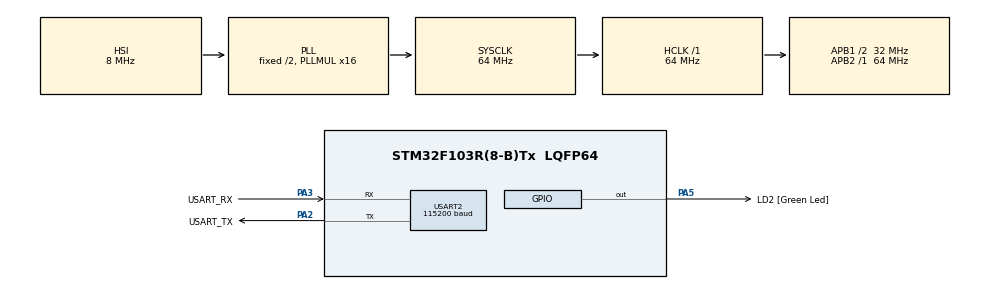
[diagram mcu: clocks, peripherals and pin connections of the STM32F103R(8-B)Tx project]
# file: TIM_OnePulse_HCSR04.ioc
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Mcu.Family=STM32F1
Mcu.Name=STM32F103R(8-B)Tx
Mcu.Package=LQFP64
NVIC.PriorityGroup=NVIC_PRIORITYGROUP_4
NVIC.TIM2_IRQn=true\:1\:0\:false\:false\:true\:true\:true\:true
PA0-WKUP.GPIO_PuPd=GPIO_PULLDOWN
PA0-WKUP.Signal=S_TIM2_CH1
PA13.GPIO_Label=TMS
PA13.Mode=Serial_Wire
PA13.Signal=SYS_JTMS-SWDIO
PA14.GPIO_Label=TCK
PA14.Mode=Serial_Wire
PA14.Signal=SYS_JTCK-SWCLK
PA2.GPIO_Label=USART_TX
PA2.GPIO_Mode=GPIO_MODE_AF_PP
PA2.GPIO_PuPd=GPIO_NOPULL
PA2.GPIO_Speed=GPIO_SPEED_FREQ_LOW
PA2.Mode=Asynchronous
PA2.Signal=USART2_TX
PA3.GPIO_Label=USART_RX
PA3.GPIO_PuPd=GPIO_NOPULL
PA3.GPIO_Speed=GPIO_SPEED_FREQ_LOW
PA3.Mode=Asynchronous
PA3.Signal=USART2_RX
PA5.GPIO_Label=LD2 [Green Led]
PA5.GPIO_ModeDefaultOutputPP=GPIO_MODE_OUTPUT_PP
PA5.GPIO_PuPd=GPIO_NOPULL
PA5.GPIO_Speed=GPIO_SPEED_FREQ_LOW
PA5.Signal=GPIO_Output
PA6.GPIO_Speed=GPIO_SPEED_FREQ_HIGH
PA6.Signal=S_TIM3_CH1
PB3.GPIO_Label=SWO
PB3.Signal=SYS_JTDO-TRACESWO
PC14-OSC32_IN.Mode=LSE-External-Oscillator
PC14-OSC32_IN.Signal=RCC_OSC32_IN
PC15-OSC32_OUT.Mode=LSE-External-Oscillator
PC15-OSC32_OUT.Signal=RCC_OSC32_OUT
PD0-OSC_IN.Mode=HSE-External-Clock-Source
PD0-OSC_IN.Signal=RCC_OSC_IN
PD1-OSC_OUT.Mode=HSE-External-Clock-Source
PD1-OSC_OUT.Signal=RCC_OSC_OUT
ProjectManager.HeapSize=0x200
ProjectManager.StackSize=0x400
ProjectManager.TargetToolchain=STM32CubeIDE
RCC.AHBFreq_Value=64000000
RCC.APB1CLKDivider=RCC_HCLK_DIV2
RCC.APB1Freq_Value=32000000
RCC.APB1TimFreq_Value=64000000
RCC.APB2Freq_Value=64000000
RCC.APB2TimFreq_Value=64000000
RCC.HCLKFreq_Value=64000000
RCC.PLLMUL=RCC_PLL_MUL16
RCC.RTCClockSelection=RCC_RTCCLKSOURCE_LSE
RCC.SYSCLKFreq_VALUE=64000000
RCC.SYSCLKSource=RCC_SYSCLKSOURCE_PLLCLK
RCC.USBFreq_Value=64000000
TIM2.Channel-Input_Capture1_from_TI1=TIM_CHANNEL_1
TIM2.Channel-Input_Capture2_from_TI1=TIM_CHANNEL_2
TIM2.IC2Polarity=TIM_INPUTCHANNELPOLARITY_FALLING
TIM2.IC2Selection=TIM_ICSELECTION_INDIRECTTI
TIM2.Period=65535
TIM2.Prescaler=63
TIM3.Channel-PWM Generation1 CH1=TIM_CHANNEL_1
TIM3.OCMode_1=TIM_OCMODE_PWM2
TIM3.Period=11
TIM3.Prescaler=63
TIM3.Pulse-PWM Generation1 CH1=2
USART2.BaudRate=115200
USART2.VirtualMode=VM_ASYNC
VP_TIM2_VS_ClockSourceINT.Mode=Internal
VP_TIM3_VS_ClockSourceINT.Mode=Internal
board=NUCLEO-F103RB

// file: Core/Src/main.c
/* USER CODE BEGIN Header */
/**
 ******************************************************************************
 * @file           : main.c
 * @brief          : Main program body
 ******************************************************************************
 * @attention
 *
 * Copyright (c) 2026 STMicroelectronics.
 * All rights reserved.
 *
 * This software is licensed under terms that can be found in the LICENSE file
 * in the root directory of this software component.
 * If no LICENSE file comes with this software, it is provided AS-IS.
 *
 ******************************************************************************
 */
/**
 * 10_TIM_OnePulse_HCSR04_c  —  [계층: HAL + 레지스터(OPM 비트)]  원 펄스 모드로 10us 트리거 + 입력 캡처로 초음파 거리 측정
 *
 * HC-SR04 초음파 센서 프로토콜
 *   TRIG 핀에 10us 이상의 High 펄스 -> 센서가 40kHz 초음파 8발 송출 -> ECHO 핀이 "왕복 시간" 동안 High
 *   거리[cm] = ECHO 폭[us] / 58   (음속 343m/s, 왕복이므로 /2)
 *
 * 배선 (Nucleo-F103RB)
 *   VCC = 5V, GND = GND
 *   TRIG = PA6 ('D12', TIM3_CH1)   <- 타이머 원 펄스 출력
 *   ECHO = PA0 ('A0', TIM2_CH1/CH2 입력 캡처)  *** ECHO 는 5V 신호이므로 저항 분압(예: 1kΩ + 2kΩ)으로 3.3V 이하로 낮출 것 ***
 *
 * 원 펄스 모드(OPM) (RM0008 15.3.10)
 *   TIM3->CR1.OPM = 1 : 카운터가 다음 업데이트 이벤트에서 스스로 멈춘다(CEN 자동 클리어).
 *   PWM 모드 2 + OPM: 카운터가 CCR1 이 되기 전에는 Low, CCR1 ~ ARR 동안 High -> "CCR1 지연 후 (ARR-CCR1+1) 폭의 펄스 1개"
 *     (RM0008 15.3.10: tPULSE = TIMx_ARR - TIMx_CCR + 1. 카운트 값 CCR1, CCR1+1, ..., ARR 이 모두 High 이므로 +1)
 *   1MHz 카운터에서 CCR1 = 2, ARR = 11  ->  2us 지연 후 (11-2+1) = 10us 폭의 High 펄스.  CEN 을 세울 때마다 펄스가 1번 나간다.
 *   -> CPU 가 10us 를 바쁜 대기하지 않고 하드웨어가 정확한 폭을 만든다.
 *
 * 에코 폭 측정: TIM2 의 CH1(상승 에지 캡처)/CH2(하강 에지 캡처, 같은 TI1 입력)  -> 폭 = CCR2 - CCR1
 *   1MHz(1us) 16비트 -> 최대 65ms (약 11m) 까지 측정 가능. HC-SR04 유효 범위 2~400cm(약 23ms) 충분.
 *
 * ISR vs 콜백
 *   TIM2_IRQHandler (stm32f1xx_it.c, 진짜 ISR) -> HAL_TIM_IRQHandler() -> HAL_TIM_IC_CaptureCallback() (이 파일)
 *   (CH2 = 하강 에지 = 에코 종료 시점에 폭이 완성된다)
 */
/* USER CODE END Header */
#include "main.h"

/* USER CODE BEGIN Includes */
#include <stdio.h>
#include <string.h>
/* USER CODE END Includes */

TIM_HandleTypeDef htim2;      /* ECHO 캡처 */
TIM_HandleTypeDef htim3;      /* TRIG 원 펄스 */
UART_HandleTypeDef huart2;

/* USER CODE BEGIN PV */
static volatile uint32_t echo_us;
static volatile uint8_t echo_ready;
/* USER CODE END PV */

void SystemClock_Config(void);
static void MX_GPIO_Init(void);
static void MX_USART2_UART_Init(void);
static void MX_TIM2_Init(void);
static void MX_TIM3_Init(void);
void HAL_TIM_MspPostInit(TIM_HandleTypeDef *htim);

int main(void)
{

  /* MCU Configuration--------------------------------------------------------*/

  /* Reset of all peripherals, Initializes the Flash interface and the Systick. */
  HAL_Init();

  /* Configure the system clock */
  SystemClock_Config();

  /* Initialize all configured peripherals */
  MX_GPIO_Init();
  MX_USART2_UART_Init();
  MX_TIM2_Init();
  MX_TIM3_Init();
  /* USER CODE BEGIN 2 */
  if (HAL_TIM_IC_Start(&htim2, TIM_CHANNEL_1) != HAL_OK) Error_Handler();      /* CH1 은 값만 캡처 (CCER.CC1E=1) */
  if (HAL_TIM_IC_Start_IT(&htim2, TIM_CHANNEL_2) != HAL_OK) Error_Handler();   /* CH2 인터럽트: DIER.CC2IE=1, 에코 종료 통지 */

  char msg[64];
  /* USER CODE END 2 */

  /* Infinite loop */
  while (1)
  {

    /* USER CODE BEGIN 3 */
    echo_ready = 0;
    htim3.Instance->CR1 |= TIM_CR1_CEN;            /* TIM3->CR1.CEN = 1 : 원 펄스 발사 -> 10us High 펄스 1개 후 자동 정지 */

    uint32_t t0 = HAL_GetTick();
    while (!echo_ready && (HAL_GetTick() - t0) < 60) {}       /* 에코 대기 (최대 60ms) */

    int n;
    if (echo_ready)
      n = snprintf(msg, sizeof msg, "echo=%lu us  distance=%lu.%lu cm\r\n", (unsigned long)echo_us,
                   (unsigned long)(echo_us / 58UL), (unsigned long)((echo_us * 10UL / 58UL) % 10UL));
    else
      n = snprintf(msg, sizeof msg, "no echo (check wiring / range)\r\n");
    HAL_UART_Transmit(&huart2, (uint8_t *)msg, (uint16_t)n, 100);
    HAL_Delay(100);                                 /* 측정 주기 (HC-SR04 권장 60ms 이상) */
  }
  /* USER CODE END 3 */
}

void SystemClock_Config(void)
{
  RCC_OscInitTypeDef RCC_OscInitStruct = {0};
  RCC_ClkInitTypeDef RCC_ClkInitStruct = {0};

  /** Initializes the RCC Oscillators according to the specified parameters
  * in the RCC_OscInitTypeDef structure.
  */
  RCC_OscInitStruct.OscillatorType = RCC_OSCILLATORTYPE_HSI;
  RCC_OscInitStruct.HSIState = RCC_HSI_ON;
  RCC_OscInitStruct.HSICalibrationValue = RCC_HSICALIBRATION_DEFAULT;
  RCC_OscInitStruct.PLL.PLLState = RCC_PLL_ON;
  RCC_OscInitStruct.PLL.PLLSource = RCC_PLLSOURCE_HSI_DIV2;
  RCC_OscInitStruct.PLL.PLLMUL = RCC_PLL_MUL16;
  if (HAL_RCC_OscConfig(&RCC_OscInitStruct) != HAL_OK)
  {
    Error_Handler();
  }

  /** Initializes the CPU, AHB and APB buses clocks
  */
  RCC_ClkInitStruct.ClockType = RCC_CLOCKTYPE_HCLK|RCC_CLOCKTYPE_SYSCLK
                              |RCC_CLOCKTYPE_PCLK1|RCC_CLOCKTYPE_PCLK2;
  RCC_ClkInitStruct.SYSCLKSource = RCC_SYSCLKSOURCE_PLLCLK;
  RCC_ClkInitStruct.AHBCLKDivider = RCC_SYSCLK_DIV1;
  RCC_ClkInitStruct.APB1CLKDivider = RCC_HCLK_DIV2;
  RCC_ClkInitStruct.APB2CLKDivider = RCC_HCLK_DIV1;

  if (HAL_RCC_ClockConfig(&RCC_ClkInitStruct, FLASH_LATENCY_2) != HAL_OK)
  {
    Error_Handler();
  }
}

static void MX_GPIO_Init(void)
{
  GPIO_InitTypeDef GPIO_InitStruct = {0};

  /* GPIO Ports Clock Enable */
  __HAL_RCC_GPIOC_CLK_ENABLE();
  __HAL_RCC_GPIOD_CLK_ENABLE();
  __HAL_RCC_GPIOA_CLK_ENABLE();
  __HAL_RCC_GPIOB_CLK_ENABLE();

  /*Configure GPIO pin Output Level */
  HAL_GPIO_WritePin(LD2_GPIO_Port, LD2_Pin, GPIO_PIN_RESET);

  /*Configure GPIO pin : LD2_Pin */
  GPIO_InitStruct.Pin = LD2_Pin;
  GPIO_InitStruct.Mode = GPIO_MODE_OUTPUT_PP;
  GPIO_InitStruct.Pull = GPIO_NOPULL;
  GPIO_InitStruct.Speed = GPIO_SPEED_FREQ_LOW;
  HAL_GPIO_Init(LD2_GPIO_Port, &GPIO_InitStruct);

}

static void MX_USART2_UART_Init(void)
{

  huart2.Instance = USART2;
  huart2.Init.BaudRate = 115200;
  huart2.Init.WordLength = UART_WORDLENGTH_8B;
  huart2.Init.StopBits = UART_STOPBITS_1;
  huart2.Init.Parity = UART_PARITY_NONE;
  huart2.Init.Mode = UART_MODE_TX_RX;
  huart2.Init.HwFlowCtl = UART_HWCONTROL_NONE;
  huart2.Init.OverSampling = UART_OVERSAMPLING_16;
  if (HAL_UART_Init(&huart2) != HAL_OK)
  {
    Error_Handler();
  }

}

static void MX_TIM2_Init(void)
{

  TIM_ClockConfigTypeDef sClockSourceConfig = {0};
  TIM_MasterConfigTypeDef sMasterConfig = {0};
  TIM_IC_InitTypeDef sConfigIC = {0};

  htim2.Instance = TIM2;
  htim2.Init.Prescaler = 63;
  htim2.Init.CounterMode = TIM_COUNTERMODE_UP;
  htim2.Init.Period = 65535;
  htim2.Init.ClockDivision = TIM_CLOCKDIVISION_DIV1;
  htim2.Init.AutoReloadPreload = TIM_AUTORELOAD_PRELOAD_DISABLE;
  if (HAL_TIM_Base_Init(&htim2) != HAL_OK)
  {
    Error_Handler();
  }
  sClockSourceConfig.ClockSource = TIM_CLOCKSOURCE_INTERNAL;
  if (HAL_TIM_ConfigClockSource(&htim2, &sClockSourceConfig) != HAL_OK)
  {
    Error_Handler();
  }
  if (HAL_TIM_IC_Init(&htim2) != HAL_OK)
  {
    Error_Handler();
  }
  sMasterConfig.MasterOutputTrigger = TIM_TRGO_RESET;
  sMasterConfig.MasterSlaveMode = TIM_MASTERSLAVEMODE_DISABLE;
  if (HAL_TIMEx_MasterConfigSynchronization(&htim2, &sMasterConfig) != HAL_OK)
  {
    Error_Handler();
  }
  sConfigIC.ICPolarity = TIM_INPUTCHANNELPOLARITY_RISING;
  sConfigIC.ICSelection = TIM_ICSELECTION_DIRECTTI;
  sConfigIC.ICPrescaler = TIM_ICPSC_DIV1;
  sConfigIC.ICFilter = 0;
  if (HAL_TIM_IC_ConfigChannel(&htim2, &sConfigIC, TIM_CHANNEL_1) != HAL_OK)
  {
    Error_Handler();
  }
  sConfigIC.ICPolarity = TIM_INPUTCHANNELPOLARITY_FALLING;
  sConfigIC.ICSelection = TIM_ICSELECTION_INDIRECTTI;
  if (HAL_TIM_IC_ConfigChannel(&htim2, &sConfigIC, TIM_CHANNEL_2) != HAL_OK)
  {
    Error_Handler();
  }
  /* USER CODE BEGIN TIM2_Init 2 */
  /* TIM2: PA0(TI1) 상승 에지 -> CCR1, 하강 에지 -> CCR2 (CCMR1.CC2S = 10: CH2 가 TI1 간접 입력). 카운터 1MHz(PSC=63) */
  /* USER CODE END TIM2_Init 2 */

}

static void MX_TIM3_Init(void)
{

  TIM_ClockConfigTypeDef sClockSourceConfig = {0};
  TIM_MasterConfigTypeDef sMasterConfig = {0};
  TIM_OC_InitTypeDef sConfigOC = {0};

  htim3.Instance = TIM3;
  htim3.Init.Prescaler = 63;
  htim3.Init.CounterMode = TIM_COUNTERMODE_UP;
  htim3.Init.Period = 11;
  htim3.Init.ClockDivision = TIM_CLOCKDIVISION_DIV1;
  htim3.Init.AutoReloadPreload = TIM_AUTORELOAD_PRELOAD_DISABLE;
  if (HAL_TIM_Base_Init(&htim3) != HAL_OK)
  {
    Error_Handler();
  }
  sClockSourceConfig.ClockSource = TIM_CLOCKSOURCE_INTERNAL;
  if (HAL_TIM_ConfigClockSource(&htim3, &sClockSourceConfig) != HAL_OK)
  {
    Error_Handler();
  }
  if (HAL_TIM_PWM_Init(&htim3) != HAL_OK)
  {
    Error_Handler();
  }
  sMasterConfig.MasterOutputTrigger = TIM_TRGO_RESET;
  sMasterConfig.MasterSlaveMode = TIM_MASTERSLAVEMODE_DISABLE;
  if (HAL_TIMEx_MasterConfigSynchronization(&htim3, &sMasterConfig) != HAL_OK)
  {
    Error_Handler();
  }
  sConfigOC.OCMode = TIM_OCMODE_PWM2;
  sConfigOC.Pulse = 2;
  sConfigOC.OCPolarity = TIM_OCPOLARITY_HIGH;
  sConfigOC.OCFastMode = TIM_OCFAST_DISABLE;
  if (HAL_TIM_PWM_ConfigChannel(&htim3, &sConfigOC, TIM_CHANNEL_1) != HAL_OK)
  {
    Error_Handler();
  }
  /* USER CODE BEGIN TIM3_Init 2 */
  /* CubeMX 가 표현하지 못하는 원 펄스 설정을 레지스터로 직접 지정 (HAL_TIM_PWM_Start 는 쓰지 않는다) */
  htim3.Instance->CR1 |= TIM_CR1_OPM;                 /* CR1.OPM = 1 : 업데이트 이벤트에서 카운터 자동 정지 */
  htim3.Instance->CCER |= TIM_CCER_CC1E;              /* CCER.CC1E = 1 : CH1 출력 활성 (CEN 은 발사 때 세움) */
  /* USER CODE END TIM3_Init 2 */
  HAL_TIM_MspPostInit(&htim3);

}

/* USER CODE BEGIN 4 */
/* ------------------------------------------------------------------------- */
/* HAL 콜백 (ISR 아님): CH2 하강 에지 = 에코 종료.                                  */
/* TIM2_IRQHandler (stm32f1xx_it.c, 진짜 ISR) -> HAL_TIM_IRQHandler() -> 이 콜백 */
/* ------------------------------------------------------------------------- */
void HAL_TIM_IC_CaptureCallback(TIM_HandleTypeDef *htim)
{
  if (htim->Instance == TIM2 && htim->Channel == HAL_TIM_ACTIVE_CHANNEL_2)
  {
    uint16_t rise = (uint16_t)HAL_TIM_ReadCapturedValue(htim, TIM_CHANNEL_1);   /* TIM2->CCR1 : 상승 에지 시각 */
    uint16_t fall = (uint16_t)HAL_TIM_ReadCapturedValue(htim, TIM_CHANNEL_2);   /* TIM2->CCR2 : 하강 에지 시각 */
    echo_us = (uint16_t)(fall - rise);              /* 16비트 래핑에 안전한 차 */
    echo_ready = 1;
  }
}
/* USER CODE END 4 */

void Error_Handler(void)
{
  __disable_irq();
  while (1) {
  }
}
#ifdef USE_FULL_ASSERT
/**
  * @brief  Reports the name of the source file and the source line number
  *         where the assert_param error has occurred.
  * @param  file: pointer to the source file name
  * @param  line: assert_param error line source number
  * @retval None
  */
void assert_failed(uint8_t *file, uint32_t line)
{
  /* USER CODE BEGIN 6 */
  /* User can add his own implementation to report the file name and line
     number, ex: printf("Wrong parameters value: file %s on line %d\r\n", file,
     line) */
  /* USER CODE END 6 */
}
#endif /* USE_FULL_ASSERT */
